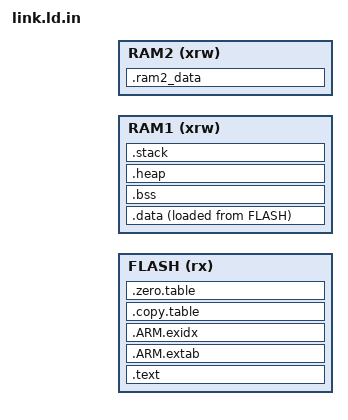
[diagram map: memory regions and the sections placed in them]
#include "region.h"

MEMORY
{
    FLASH (rx)  : ORIGIN = __IROM_BASE, LENGTH = __IROM_SIZE
    RAM1  (xrw) : ORIGIN = __RAM1_BASE, LENGTH = __RAM1_SIZE
    RAM2  (xrw) : ORIGIN = __RAM2_BASE, LENGTH = __RAM2_SIZE
}

ENTRY(Reset_Handler)

SECTIONS
{
    .text :
    {
        KEEP(*(.vectors))

        *(.text*)

        KEEP (*(.init))
        KEEP (*(.fini))

        /* .ctors */
        *crtbegin.o(.ctors)
        *crtbegin?.o(.ctors)
        *(EXCLUDE_FILE(*crtend?.o *crtend.o) .ctors)
        *(SORT(.ctors.*))
        *(.ctors)

        /* .dtors */
        *crtbegin.o(.dtors)
        *crtbegin?.o(.dtors)
        *(EXCLUDE_FILE(*crtend?.o *crtend.o) .dtors)
        *(SORT(.dtors.*))
        *(.dtors)

        *(.rodata*)

        KEEP(*(.eh_frame*))
    } >FLASH

    .ARM.extab : { 
        *(.ARM.extab* .gnu.linkonce.armextab.*)
    } >FLASH

    .ARM.exidx : {
        __exidx_start = .;

        *(.ARM.exidx* .gnu.linkonce.armexidx.*)

        __exidx_end = .;
    } > FLASH

    .copy.table :
    {
        . = ALIGN(4);

        __copy_table_start__ = .;

        LONG (LOADADDR(.data))
        LONG (ADDR(.data))
        LONG (SIZEOF(.data) / 4)

        __copy_table_end__ = .;
    } > FLASH

    .zero.table :
    {
        . = ALIGN(4);

        __zero_table_start__ = .;
        __zero_table_end__ = .;
    } > FLASH

    PROVIDE(__etext = LOADADDR(.data));

    .data : ALIGN(4)
    {
        __data_start__ = .;

        *(vtable)
        *(.data)
        *(.data.*)

        . = ALIGN(4);

        PROVIDE_HIDDEN (__preinit_array_start = .);
        KEEP(*(.preinit_array))
        PROVIDE_HIDDEN (__preinit_array_end = .);

        . = ALIGN(4);

        PROVIDE_HIDDEN (__init_array_start = .);
        KEEP(*(SORT(.init_array.*)))
        KEEP(*(.init_array))
        PROVIDE_HIDDEN (__init_array_end = .);

        . = ALIGN(4);

        PROVIDE_HIDDEN (__fini_array_start = .);
        KEEP(*(SORT(.fini_array.*)))
        KEEP(*(.fini_array))
        PROVIDE_HIDDEN (__fini_array_end = .);

        . = ALIGN(4);

        __data_end__ = .;
    } > RAM1 AT > FLASH

    .bss :
    {
        . = ALIGN(4);

        __bss_start__ = .;

        *(.bss)
        *(.bss.*)
        *(COMMON)

        . = ALIGN(4);

        __bss_end__ = .;
    } > RAM1 AT > RAM1

    .heap (NOLOAD) :
    {
        . = ALIGN(8);

        __end__ = .;
        PROVIDE(end = .);

        KEEP(*(.freertos_heap))

        . = ALIGN(8);

        __HeapLimit = .;
    } > RAM1

    .stack (ORIGIN(RAM1) + LENGTH(RAM1) - __STACK_SIZE) (NOLOAD) :
    {
        . = ALIGN(8);

        __StackLimit = .;

        . += __STACK_SIZE;

        . = ALIGN(8);

        __StackTop = .;
    } > RAM1

    PROVIDE(__stack = __StackTop);

    ASSERT(__StackLimit >= __HeapLimit, "region RAM1 overflowed with stack")

    .ram2_data (NOLOAD) :
    {
        . = ALIGN(4);

        __ram2_start__ = .;

        *(.ram2_data*)

        . = ALIGN(4);

        __ram2_end__ = .;
    } >RAM2
}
